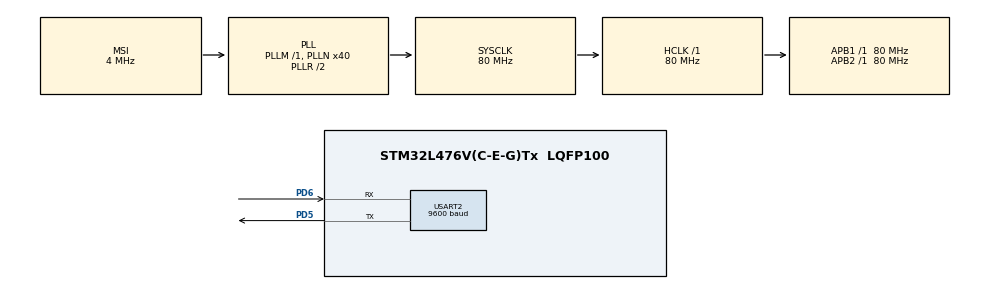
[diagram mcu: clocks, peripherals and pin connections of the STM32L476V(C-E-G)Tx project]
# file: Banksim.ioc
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FREERTOS.CountingSemaphores01=heartbeat,2,Dynamic,NULL
FREERTOS.Tasks01=MainTask,24,128,StartMainTask,Default,NULL,Dynamic,NULL,NULL;Teller1,24,128,StartTeller1,Default,NULL,Dynamic,NULL,NULL;Teller2,24,128,StartTeller2,Default,NULL,Dynamic,NULL,NULL;Teller3,8,128,StartTeller3,Default,NULL,Dynamic,NULL,NULL;Heartbeat,32,128,StartHB,Default,NULL,Dynamic,NULL,NULL
FREERTOS.Timers01=HB_Timer,HB_Timer_Callback,osTimerPeriodic,Default,NULL,Dynamic,NULL
FREERTOS.configTOTAL_HEAP_SIZE=4000
Mcu.Family=STM32L4
Mcu.Name=STM32L476V(C-E-G)Tx
Mcu.Package=LQFP100
NVIC.PriorityGroup=NVIC_PRIORITYGROUP_4
NVIC.RCC_IRQn=true\:5\:0\:false\:false\:true\:true\:true\:false
NVIC.TIM6_DAC_IRQn=true\:0\:0\:false\:false\:true\:false\:false\:true
NVIC.TimeBase=TIM6_DAC_IRQn
NVIC.TimeBaseIP=TIM6
PD5.Mode=Asynchronous
PD5.Signal=USART2_TX
PD6.Mode=Asynchronous
PD6.Signal=USART2_RX
PH0-OSC_IN\ (PH0).Mode=HSE-External-Clock-Source
PH0-OSC_IN\ (PH0).Signal=RCC_OSC_IN
ProjectManager.HeapSize=0x200
ProjectManager.StackSize=0x400
ProjectManager.TargetToolchain=STM32CubeIDE
RCC.ADCFreq_Value=32000000
RCC.AHBFreq_Value=80000000
RCC.APB1Freq_Value=80000000
RCC.APB1TimFreq_Value=80000000
RCC.APB2Freq_Value=80000000
RCC.APB2TimFreq_Value=80000000
RCC.CortexFreq_Value=80000000
RCC.HCLKFreq_Value=80000000
RCC.HSE_VALUE=8000000
RCC.HSI_VALUE=16000000
RCC.LSE_VALUE=32768
RCC.MSI_VALUE=4000000
RCC.PLLN=40
RCC.PLLSAI1N=16
RCC.PREFETCH_ENABLE=1
RCC.SYSCLKFreq_VALUE=80000000
RCC.SYSCLKSource=RCC_SYSCLKSOURCE_PLLCLK
RCC.USBFreq_Value=32000000
RCC.VCOOutputFreq_Value=160000000
USART2.BaudRate=9600
USART2.VirtualMode-Asynchronous=VM_ASYNC
VP_FREERTOS_VS_CMSIS_V2.Mode=CMSIS_V2
VP_RNG_VS_RNG.Mode=RNG_Activate
VP_SYS_VS_tim6.Mode=TIM6
board=STM32L476G-DISCO

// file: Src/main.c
/* USER CODE BEGIN Header */
/**
  ******************************************************************************
  * @file           : main.c
  * @brief          : Main program body
  ******************************************************************************
  * @attention
  *
  * <h2><center>&copy; Copyright (c) 2020 STMicroelectronics.
  * All rights reserved.</center></h2>
  *
  * This software component is licensed by ST under Ultimate Liberty license
  * SLA0044, the "License"; You may not use this file except in compliance with
  * the License. You may obtain a copy of the License at:
  *                             www.st.com/SLA0044
  *
  ******************************************************************************
  */
/* USER CODE END Header */

#include "main.h"
#include "cmsis_os.h"

RNG_HandleTypeDef hrng;

UART_HandleTypeDef huart2;

/* Definitions for MainTask */
osThreadId_t MainTaskHandle;
const osThreadAttr_t MainTask_attributes = {
  .name = "MainTask",
  .priority = (osPriority_t) osPriorityNormal,
  .stack_size = 128
};
/* Definitions for Teller1 */
osThreadId_t Teller1Handle;
const osThreadAttr_t Teller1_attributes = {
  .name = "Teller1",
  .priority = (osPriority_t) osPriorityNormal,
  .stack_size = 128
};
/* Definitions for Teller2 */
osThreadId_t Teller2Handle;
const osThreadAttr_t Teller2_attributes = {
  .name = "Teller2",
  .priority = (osPriority_t) osPriorityNormal,
  .stack_size = 128
};
/* Definitions for Teller3 */
osThreadId_t Teller3Handle;
const osThreadAttr_t Teller3_attributes = {
  .name = "Teller3",
  .priority = (osPriority_t) osPriorityLow,
  .stack_size = 128
};
/* Definitions for Heartbeat */
osThreadId_t HeartbeatHandle;
const osThreadAttr_t Heartbeat_attributes = {
  .name = "Heartbeat",
  .priority = (osPriority_t) osPriorityAboveNormal,
  .stack_size = 128
};
/* Definitions for HB_Timer */
osTimerId_t HB_TimerHandle;
const osTimerAttr_t HB_Timer_attributes = {
  .name = "HB_Timer"
};
/* Definitions for heartbeat */
osSemaphoreId_t heartbeatHandle;
const osSemaphoreAttr_t heartbeat_attributes = {
  .name = "heartbeat"
};

void SystemClock_Config(void);
static void MX_GPIO_Init(void);
static void MX_USART2_UART_Init(void);
static void MX_RNG_Init(void);
void StartMainTask(void *argument);
void StartTeller1(void *argument);
void StartTeller2(void *argument);
void StartTeller3(void *argument);
void StartHB(void *argument);
void HB_Timer_Callback(void *argument);

int main(void)
{

  /* MCU Configuration--------------------------------------------------------*/

  /* Reset of all peripherals, Initializes the Flash interface and the Systick. */
  HAL_Init();

  /* Configure the system clock */
  SystemClock_Config();

  /* Initialize all configured peripherals */
  MX_GPIO_Init();
  MX_USART2_UART_Init();
  MX_RNG_Init();
  /* Init scheduler */
  osKernelInitialize();

  /* Create the semaphores(s) */
  /* creation of heartbeat */
  heartbeatHandle = osSemaphoreNew(2, 2, &heartbeat_attributes);

  /* Create the timer(s) */
  /* creation of HB_Timer */
  HB_TimerHandle = osTimerNew(HB_Timer_Callback, osTimerPeriodic, NULL, &HB_Timer_attributes);

  /* USER CODE BEGIN RTOS_TIMERS */
  /* start timers, add new ones, ... */
  /*
  int timerDelay = 10; // In OS Ticks a.k.a. ms (i think)

  status = osTimerStart (periodic_id, timerDelay);
  if (status != osOK) {
	  // Error: Timer could not be started
	  status = osTimerStop (periodic_id);
  }
  */
  /* USER CODE END RTOS_TIMERS */

  uint8_t buffer[13] = "Hello World\n\r";
  HAL_UART_Transmit(&huart2, buffer, 13, HAL_MAX_DELAY);
  /* Create the thread(s) */
  /* creation of MainTask */
  MainTaskHandle = osThreadNew(StartMainTask, NULL, &MainTask_attributes);

  /* creation of Teller1 */
  Teller1Handle = osThreadNew(StartTeller1, NULL, &Teller1_attributes);

  /* creation of Teller2 */
  Teller2Handle = osThreadNew(StartTeller2, NULL, &Teller2_attributes);

  /* creation of Teller3 */
  Teller3Handle = osThreadNew(StartTeller3, NULL, &Teller3_attributes);

  /* creation of Heartbeat */
  HeartbeatHandle = osThreadNew(StartHB, NULL, &Heartbeat_attributes);

  /* Start scheduler */
  osKernelStart();

  /* We should never get here as control is now taken by the scheduler */

  /* Infinite loop */
  while (1)
  {

  }
}

void SystemClock_Config(void)
{
  RCC_OscInitTypeDef RCC_OscInitStruct = {0};
  RCC_ClkInitTypeDef RCC_ClkInitStruct = {0};
  RCC_PeriphCLKInitTypeDef PeriphClkInit = {0};

  /** Initializes the CPU, AHB and APB busses clocks
  */
  RCC_OscInitStruct.OscillatorType = RCC_OSCILLATORTYPE_MSI;
  RCC_OscInitStruct.MSIState = RCC_MSI_ON;
  RCC_OscInitStruct.MSICalibrationValue = 0;
  RCC_OscInitStruct.MSIClockRange = RCC_MSIRANGE_6;
  RCC_OscInitStruct.PLL.PLLState = RCC_PLL_ON;
  RCC_OscInitStruct.PLL.PLLSource = RCC_PLLSOURCE_MSI;
  RCC_OscInitStruct.PLL.PLLM = 1;
  RCC_OscInitStruct.PLL.PLLN = 40;
  RCC_OscInitStruct.PLL.PLLP = RCC_PLLP_DIV7;
  RCC_OscInitStruct.PLL.PLLQ = RCC_PLLQ_DIV2;
  RCC_OscInitStruct.PLL.PLLR = RCC_PLLR_DIV2;
  if (HAL_RCC_OscConfig(&RCC_OscInitStruct) != HAL_OK)
  {
    Error_Handler();
  }
  /** Initializes the CPU, AHB and APB busses clocks
  */
  RCC_ClkInitStruct.ClockType = RCC_CLOCKTYPE_HCLK|RCC_CLOCKTYPE_SYSCLK
                              |RCC_CLOCKTYPE_PCLK1|RCC_CLOCKTYPE_PCLK2;
  RCC_ClkInitStruct.SYSCLKSource = RCC_SYSCLKSOURCE_PLLCLK;
  RCC_ClkInitStruct.AHBCLKDivider = RCC_SYSCLK_DIV1;
  RCC_ClkInitStruct.APB1CLKDivider = RCC_HCLK_DIV1;
  RCC_ClkInitStruct.APB2CLKDivider = RCC_HCLK_DIV1;

  if (HAL_RCC_ClockConfig(&RCC_ClkInitStruct, FLASH_LATENCY_4) != HAL_OK)
  {
    Error_Handler();
  }
  PeriphClkInit.PeriphClockSelection = RCC_PERIPHCLK_USART2|RCC_PERIPHCLK_RNG;
  PeriphClkInit.Usart2ClockSelection = RCC_USART2CLKSOURCE_PCLK1;
  PeriphClkInit.RngClockSelection = RCC_RNGCLKSOURCE_PLLSAI1;
  PeriphClkInit.PLLSAI1.PLLSAI1Source = RCC_PLLSOURCE_MSI;
  PeriphClkInit.PLLSAI1.PLLSAI1M = 1;
  PeriphClkInit.PLLSAI1.PLLSAI1N = 16;
  PeriphClkInit.PLLSAI1.PLLSAI1P = RCC_PLLP_DIV7;
  PeriphClkInit.PLLSAI1.PLLSAI1Q = RCC_PLLQ_DIV2;
  PeriphClkInit.PLLSAI1.PLLSAI1R = RCC_PLLR_DIV2;
  PeriphClkInit.PLLSAI1.PLLSAI1ClockOut = RCC_PLLSAI1_48M2CLK;
  if (HAL_RCCEx_PeriphCLKConfig(&PeriphClkInit) != HAL_OK)
  {
    Error_Handler();
  }
  /** Configure the main internal regulator output voltage
  */
  if (HAL_PWREx_ControlVoltageScaling(PWR_REGULATOR_VOLTAGE_SCALE1) != HAL_OK)
  {
    Error_Handler();
  }
}

static void MX_RNG_Init(void)
{

  hrng.Instance = RNG;
  if (HAL_RNG_Init(&hrng) != HAL_OK)
  {
    Error_Handler();
  }

}

static void MX_USART2_UART_Init(void)
{

  huart2.Instance = USART2;
  huart2.Init.BaudRate = 9600;
  huart2.Init.WordLength = UART_WORDLENGTH_8B;
  huart2.Init.StopBits = UART_STOPBITS_1;
  huart2.Init.Parity = UART_PARITY_NONE;
  huart2.Init.Mode = UART_MODE_TX_RX;
  huart2.Init.HwFlowCtl = UART_HWCONTROL_NONE;
  huart2.Init.OverSampling = UART_OVERSAMPLING_16;
  huart2.Init.OneBitSampling = UART_ONE_BIT_SAMPLE_DISABLE;
  huart2.AdvancedInit.AdvFeatureInit = UART_ADVFEATURE_NO_INIT;
  if (HAL_UART_Init(&huart2) != HAL_OK)
  {
    Error_Handler();
  }

}

static void MX_GPIO_Init(void)
{

  /* GPIO Ports Clock Enable */
  __HAL_RCC_GPIOH_CLK_ENABLE();
  __HAL_RCC_GPIOD_CLK_ENABLE();

}

void StartMainTask(void *argument)
{
	for(;;)
  {
    osDelay(1);
  }
}

void StartTeller1(void *argument)
{
  for(;;)
  {
    osDelay(1);
  }
}

void StartTeller2(void *argument)
{
  for(;;)
  {
    osDelay(1);
  }
}

void StartTeller3(void *argument)
{
  for(;;)
  {
    osDelay(1);
  }
}

void StartHB(void *argument)
{
  for(;;)
  {
    osDelay(1);
  }
}

/* HB_Timer_Callback function */
void HB_Timer_Callback(void *argument)
{
}

void HAL_TIM_PeriodElapsedCallback(TIM_HandleTypeDef *htim)
{
  if (htim->Instance == TIM6) {
    HAL_IncTick();
  }
}

void Error_Handler(void)
{
}

/************************ (C) COPYRIGHT STMicroelectronics *****END OF FILE****/
